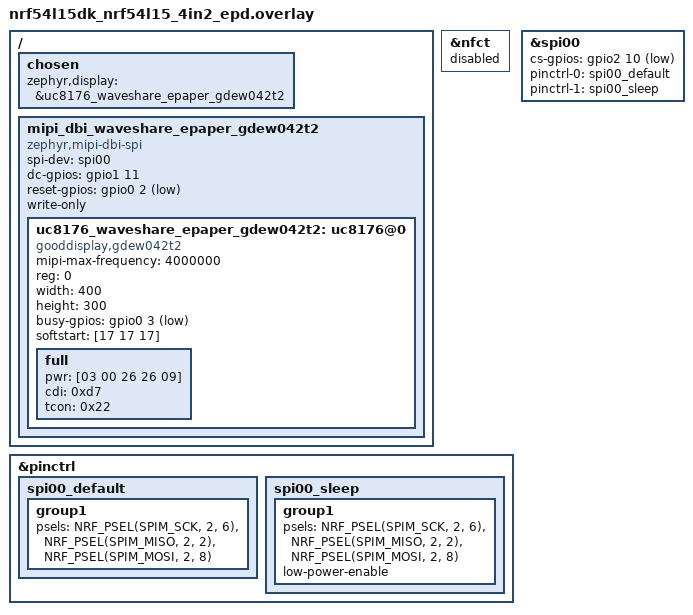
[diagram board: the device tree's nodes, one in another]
#include "nrf54l15dk_nrf54l15_memory.dtsi"

/ {
	chosen {
		zephyr,display = &uc8176_waveshare_epaper_gdew042t2;
	};

	mipi_dbi_waveshare_epaper_gdew042t2 {
		compatible = "zephyr,mipi-dbi-spi";
		spi-dev = <&spi00>;
		dc-gpios = <&gpio1 11 GPIO_ACTIVE_HIGH>;
		reset-gpios = <&gpio0 2 GPIO_ACTIVE_LOW>;
		write-only;
		#address-cells = <1>;
		#size-cells = <0>;

		uc8176_waveshare_epaper_gdew042t2: uc8176@0 {
			compatible = "gooddisplay,gdew042t2", "ultrachip,uc8176";
			mipi-max-frequency = <4000000>;
			reg = <0>;
			width = <400>;
			height = <300>;
			busy-gpios = <&gpio0 3 GPIO_ACTIVE_LOW>;

			softstart = [17 17 17];

			full {
				pwr = [03 00 26 26 09];
				cdi = <0xd7>;
				tcon = <0x22>;
			};
		};
	};

};

&nfct {
	status = "disabled";
};

&pinctrl {
	spi00_default: spi00_default {
		group1 {
			// nordic,drive-mode = <NRF_DRIVE_H0H1>;
			psels = <NRF_PSEL(SPIM_SCK, 2, 6)>,
			        <NRF_PSEL(SPIM_MISO, 2, 2)>,
			        <NRF_PSEL(SPIM_MOSI, 2, 8)>;
		};
	};

	spi00_sleep: spi00_sleep {
		group1 {
			psels = <NRF_PSEL(SPIM_SCK, 2, 6)>,
			        <NRF_PSEL(SPIM_MISO, 2, 2)>,
			        <NRF_PSEL(SPIM_MOSI, 2, 8)>;
			low-power-enable;
		};
	};

};

&spi00 {
	status = "okay";
	cs-gpios = <&gpio2 10 GPIO_ACTIVE_LOW>;
	pinctrl-0 = <&spi00_default>;
	pinctrl-1 = <&spi00_sleep>;
	pinctrl-names = "default", "sleep";
};
